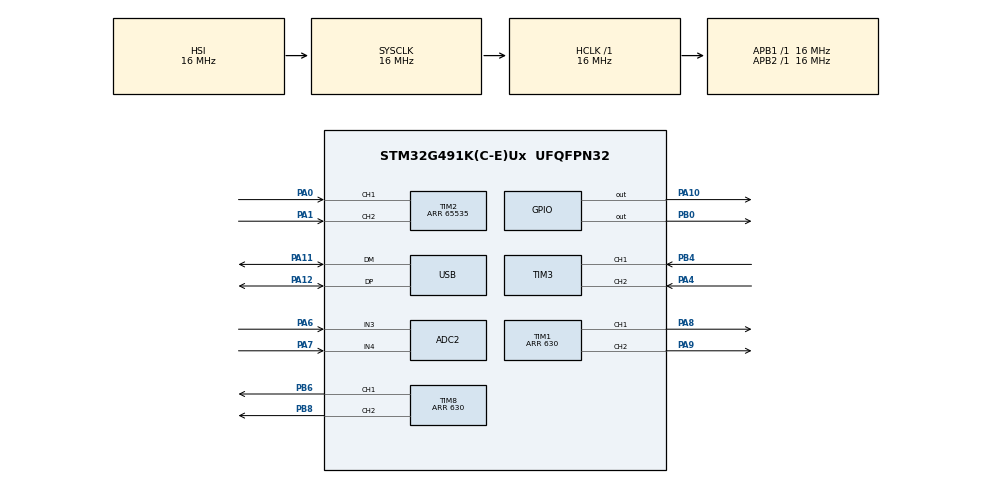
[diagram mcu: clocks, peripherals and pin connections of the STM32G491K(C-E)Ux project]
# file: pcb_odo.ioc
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ADC2.Channel-0\#ChannelRegularConversion=ADC_CHANNEL_3
ADC2.NbrOfConversionFlag=1
ADC2.OffsetNumber-0\#ChannelRegularConversion=ADC_OFFSET_NONE
ADC2.Rank-0\#ChannelRegularConversion=1
ADC2.SamplingTime-0\#ChannelRegularConversion=ADC_SAMPLETIME_2CYCLES_5
ADC2.SingleDiff-0\#ChannelRegularConversion=ADC_DIFFERENTIAL_ENDED
Mcu.Family=STM32G4
Mcu.Name=STM32G491K(C-E)Ux
Mcu.Package=UFQFPN32
NVIC.PriorityGroup=NVIC_PRIORITYGROUP_4
NVIC.USB_LP_IRQn=true\:0\:0\:false\:false\:true\:false\:true\:true
PA0.GPIO_PuPd=GPIO_PULLUP
PA0.GPIO_Speed=GPIO_SPEED_FREQ_HIGH
PA0.Signal=S_TIM2_CH1
PA1.GPIO_ModeDefaultPP=GPIO_MODE_AF_PP
PA1.GPIO_PuPd=GPIO_PULLUP
PA1.GPIO_Speed=GPIO_SPEED_FREQ_HIGH
PA1.Signal=S_TIM2_CH2
PA10.Signal=GPIO_Output
PA11.Mode=Device
PA11.Signal=USB_DM
PA12.Mode=Device
PA12.Signal=USB_DP
PA13.Signal=SYS_JTMS-SWDIO
PA14.Signal=SYS_JTCK-SWCLK
PA4.GPIO_PuPd=GPIO_PULLUP
PA4.GPIO_Speed=GPIO_SPEED_FREQ_HIGH
PA4.Signal=S_TIM3_CH2
PA6.Mode=IN3-Differential
PA6.Signal=ADC2_IN3
PA7.Mode=IN3-Differential
PA7.Signal=ADC2_IN4
PA8.Signal=S_TIM1_CH1
PA9.Signal=S_TIM1_CH2
PB0.Signal=GPIO_Output
PB3.Signal=SYS_JTDO-SWO
PB4.GPIO_PuPd=GPIO_PULLUP
PB4.GPIO_Speed=GPIO_SPEED_FREQ_HIGH
PB4.Signal=S_TIM3_CH1
PB6.Signal=S_TIM8_CH1
PB8-BOOT0.Signal=S_TIM8_CH2
PF0-OSC_IN.Mode=HSE-External-Clock-Source
PF0-OSC_IN.Signal=RCC_OSC_IN
ProjectManager.HeapSize=0x200
ProjectManager.StackSize=0x400
ProjectManager.TargetToolchain=CMake
RCC.AHBFreq_Value=16000000
RCC.APB1Freq_Value=16000000
RCC.APB1TimFreq_Value=16000000
RCC.APB2Freq_Value=16000000
RCC.APB2TimFreq_Value=16000000
RCC.CortexFreq_Value=16000000
RCC.EXTERNAL_CLOCK_VALUE=12288000
RCC.HCLKFreq_Value=16000000
RCC.HSE_VALUE=8000000
RCC.HSI48_VALUE=48000000
RCC.HSI_VALUE=16000000
RCC.LSE_VALUE=32768
RCC.SYSCLKFreq_VALUE=16000000
RCC.VCOOutputFreq_Value=128000000
SH.S_TIM1_CH1.0=TIM1_CH1,PWM Generation1 CH1
SH.S_TIM1_CH2.0=TIM1_CH2,PWM Generation2 CH2
SH.S_TIM2_CH1.0=TIM2_CH1,Encoder_Interface
SH.S_TIM2_CH2.0=TIM2_CH2,Encoder_Interface
SH.S_TIM3_CH1.0=TIM3_CH1,Encoder_Interface
SH.S_TIM3_CH2.0=TIM3_CH2,Encoder_Interface
SH.S_TIM8_CH1.0=TIM8_CH1,PWM Generation1 CH1
SH.S_TIM8_CH2.0=TIM8_CH2,PWM Generation2 CH2
TIM1.AutoReloadPreload=TIM_AUTORELOAD_PRELOAD_ENABLE
TIM1.Channel-PWM\ Generation1\ CH1=TIM_CHANNEL_1
TIM1.Channel-PWM\ Generation2\ CH2=TIM_CHANNEL_2
TIM1.PeriodNoDither=630
TIM2.EncoderMode=TIM_ENCODERMODE_TI12
TIM2.PeriodNoDither=65535
TIM3.EncoderMode=TIM_ENCODERMODE_TI12
TIM6.AutoReloadPreload=TIM_AUTORELOAD_PRELOAD_ENABLE
TIM6.Prescaler=15
TIM8.AutoReloadPreload=TIM_AUTORELOAD_PRELOAD_ENABLE
TIM8.Channel-PWM\ Generation1\ CH1=TIM_CHANNEL_1
TIM8.Channel-PWM\ Generation2\ CH2=TIM_CHANNEL_2
TIM8.PeriodNoDither=630
USB_DEVICE.CLASS_NAME_FS=CDC
USB_DEVICE.VirtualMode=Cdc
USB_DEVICE.VirtualModeFS=Cdc_FS
VP_SYS_VS_DBSignals.Mode=DisableDeadBatterySignals
VP_TIM1_VS_ClockSourceINT.Mode=Internal
VP_TIM6_VS_ClockSourceINT.Mode=Enable_Timer
VP_TIM8_VS_ClockSourceINT.Mode=Internal
VP_USB_DEVICE_VS_USB_DEVICE_CDC_FS.Mode=CDC_FS
board=custom

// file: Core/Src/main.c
/* USER CODE BEGIN Header */
/**
  ******************************************************************************
  * @file           : main.c
  * @brief          : Main program body
  ******************************************************************************
  * @attention
  *
  * Copyright (c) 2025 STMicroelectronics.
  * All rights reserved.
  *
  * This software is licensed under terms that can be found in the LICENSE file
  * in the root directory of this software component.
  * If no LICENSE file comes with this software, it is provided AS-IS.
  *
  ******************************************************************************
  */
/* USER CODE END Header */
#include "main.h"
#include "adc.h"
#include "tim.h"
#include "usb_device.h"
#include "gpio.h"

/* USER CODE BEGIN Includes */
#include "setup.h"
/* USER CODE END Includes */

void SystemClock_Config(void);

int main(void)
{

  /* MCU Configuration--------------------------------------------------------*/

  /* Reset of all peripherals, Initializes the Flash interface and the Systick. */
  HAL_Init();

  /* Configure the system clock */
  SystemClock_Config();

  /* Initialize all configured peripherals */
  MX_GPIO_Init();
  MX_TIM2_Init();
  MX_TIM1_Init();
  MX_TIM3_Init();
  MX_USB_Device_Init();
  MX_TIM8_Init();
  MX_TIM6_Init();
  MX_ADC2_Init();
  /* USER CODE BEGIN 2 */

  HAL_TIM_PWM_Start(&htim8, TIM_CHANNEL_1); // IN1A
  HAL_TIM_PWM_Start(&htim8, TIM_CHANNEL_2); // IN2A
  HAL_TIM_PWM_Start(&htim1, TIM_CHANNEL_1); // IN1B
  HAL_TIM_PWM_Start(&htim1, TIM_CHANNEL_2); // IN2B
  HAL_TIM_Encoder_Start(&htim3, TIM_CHANNEL_ALL);
  HAL_TIM_Encoder_Start(&htim2, TIM_CHANNEL_ALL);

  ModelecOdometrySetup();

  /* USER CODE END 2 */

  /* Infinite loop */
  /* USER CODE BEGIN WHILE */

  while (1)
  {

	  ModelecOdometryLoop();

    /* USER CODE END WHILE */

  }
}

void SystemClock_Config(void)
{
  RCC_OscInitTypeDef RCC_OscInitStruct = {0};
  RCC_ClkInitTypeDef RCC_ClkInitStruct = {0};

  /** Configure the main internal regulator output voltage
  */
  HAL_PWREx_ControlVoltageScaling(PWR_REGULATOR_VOLTAGE_SCALE1);

  /** Initializes the RCC Oscillators according to the specified parameters
  * in the RCC_OscInitTypeDef structure.
  */
  RCC_OscInitStruct.OscillatorType = RCC_OSCILLATORTYPE_HSI|RCC_OSCILLATORTYPE_HSI48;
  RCC_OscInitStruct.HSIState = RCC_HSI_ON;
  RCC_OscInitStruct.HSICalibrationValue = RCC_HSICALIBRATION_DEFAULT;
  RCC_OscInitStruct.HSI48State = RCC_HSI48_ON;
  RCC_OscInitStruct.PLL.PLLState = RCC_PLL_NONE;
  if (HAL_RCC_OscConfig(&RCC_OscInitStruct) != HAL_OK)
  {
    Error_Handler();
  }

  /** Initializes the CPU, AHB and APB buses clocks
  */
  RCC_ClkInitStruct.ClockType = RCC_CLOCKTYPE_HCLK|RCC_CLOCKTYPE_SYSCLK
                              |RCC_CLOCKTYPE_PCLK1|RCC_CLOCKTYPE_PCLK2;
  RCC_ClkInitStruct.SYSCLKSource = RCC_SYSCLKSOURCE_HSI;
  RCC_ClkInitStruct.AHBCLKDivider = RCC_SYSCLK_DIV1;
  RCC_ClkInitStruct.APB1CLKDivider = RCC_HCLK_DIV1;
  RCC_ClkInitStruct.APB2CLKDivider = RCC_HCLK_DIV1;

  if (HAL_RCC_ClockConfig(&RCC_ClkInitStruct, FLASH_LATENCY_0) != HAL_OK)
  {
    Error_Handler();
  }
}

void Error_Handler(void)
{
  __disable_irq();
  while (1)
  {
  }
}
